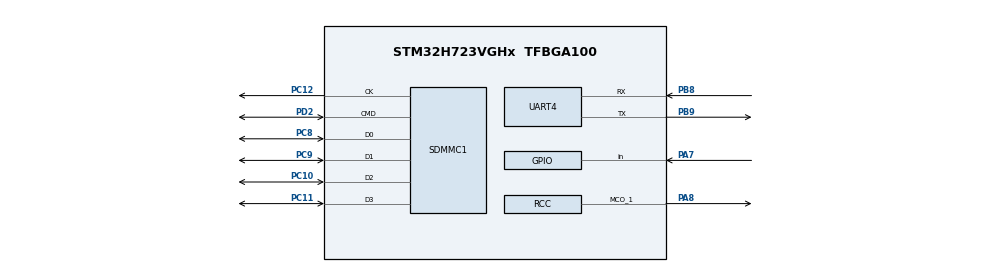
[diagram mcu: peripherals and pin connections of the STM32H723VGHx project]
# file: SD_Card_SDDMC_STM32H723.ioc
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Dma.DMA_GENERATOR0.0.Direction=DMA_PERIPH_TO_MEMORY
Dma.DMA_GENERATOR0.0.EventEnable=DISABLE
Dma.DMA_GENERATOR0.0.FIFOMode=DMA_FIFOMODE_ENABLE
Dma.DMA_GENERATOR0.0.FIFOThreshold=DMA_FIFO_THRESHOLD_FULL
Dma.DMA_GENERATOR0.0.Instance=DMA1_Stream1
Dma.DMA_GENERATOR0.0.MemBurst=DMA_MBURST_SINGLE
Dma.DMA_GENERATOR0.0.MemDataAlignment=DMA_MDATAALIGN_WORD
Dma.DMA_GENERATOR0.0.MemInc=DMA_MINC_ENABLE
Dma.DMA_GENERATOR0.0.Mode=DMA_NORMAL
Dma.DMA_GENERATOR0.0.PeriphBurst=DMA_PBURST_SINGLE
Dma.DMA_GENERATOR0.0.PeriphDataAlignment=DMA_PDATAALIGN_WORD
Dma.DMA_GENERATOR0.0.PeriphInc=DMA_PINC_DISABLE
Dma.DMA_GENERATOR0.0.Polarity=HAL_DMAMUX_REQ_GEN_RISING
Dma.DMA_GENERATOR0.0.Priority=DMA_PRIORITY_LOW
Dma.DMA_GENERATOR0.0.RequestNumber=1
Dma.DMA_GENERATOR0.0.SignalID=NONE
Dma.DMA_GENERATOR0.0.SyncEnable=DISABLE
Dma.DMA_GENERATOR0.0.SyncPolarity=HAL_DMAMUX_SYNC_NO_EVENT
Dma.DMA_GENERATOR0.0.SyncRequestNumber=1
Dma.DMA_GENERATOR0.0.SyncSignalID=NONE
Dma.DMA_GENERATOR1.1.Direction=DMA_MEMORY_TO_PERIPH
Dma.DMA_GENERATOR1.1.EventEnable=DISABLE
Dma.DMA_GENERATOR1.1.FIFOMode=DMA_FIFOMODE_ENABLE
Dma.DMA_GENERATOR1.1.FIFOThreshold=DMA_FIFO_THRESHOLD_FULL
Dma.DMA_GENERATOR1.1.Instance=DMA1_Stream0
Dma.DMA_GENERATOR1.1.MemBurst=DMA_MBURST_SINGLE
Dma.DMA_GENERATOR1.1.MemDataAlignment=DMA_MDATAALIGN_WORD
Dma.DMA_GENERATOR1.1.MemInc=DMA_MINC_ENABLE
Dma.DMA_GENERATOR1.1.Mode=DMA_NORMAL
Dma.DMA_GENERATOR1.1.PeriphBurst=DMA_PBURST_SINGLE
Dma.DMA_GENERATOR1.1.PeriphDataAlignment=DMA_PDATAALIGN_WORD
Dma.DMA_GENERATOR1.1.PeriphInc=DMA_PINC_DISABLE
Dma.DMA_GENERATOR1.1.Polarity=HAL_DMAMUX_REQ_GEN_RISING
Dma.DMA_GENERATOR1.1.Priority=DMA_PRIORITY_LOW
Dma.DMA_GENERATOR1.1.RequestNumber=1
Dma.DMA_GENERATOR1.1.SignalID=NONE
Dma.DMA_GENERATOR1.1.SyncEnable=DISABLE
Dma.DMA_GENERATOR1.1.SyncPolarity=HAL_DMAMUX_SYNC_NO_EVENT
Dma.DMA_GENERATOR1.1.SyncRequestNumber=1
Dma.DMA_GENERATOR1.1.SyncSignalID=NONE
Dma.Request0=DMA_GENERATOR0
Dma.Request1=DMA_GENERATOR1
FATFS.BSP.number=1
FATFS.USE_DMA_CODE_SD=1
FATFS._USE_CHMOD=1
FATFS._USE_EXPAND=1
FATFS._USE_FIND=1
FATFS._USE_FORWARD=1
FATFS._USE_LABEL=1
FATFS._USE_LFN=3
FATFS0.BSP.STBoard=false
FATFS0.BSP.api=Unknown
FATFS0.BSP.instance=PA7
FATFS0.BSP.ip=GPIO
FATFS0.BSP.mode=Input
FATFS0.BSP.name=Detect_SDIO
FATFS0.BSP.solution=PA7
Mcu.Family=STM32H7
Mcu.Name=STM32H723VGHx
Mcu.Package=TFBGA100
NVIC.PriorityGroup=NVIC_PRIORITYGROUP_4
NVIC.SDMMC1_IRQn=true\:0\:0\:false\:false\:true\:true\:true\:true
PA7.Signal=GPIO_Input
PA8.Mode=Clock-out-1
PA8.Signal=RCC_MCO_1
PB8.Mode=Asynchronous
PB8.Signal=UART4_RX
PB9.Mode=Asynchronous
PB9.Signal=UART4_TX
PC10.Mode=SD_4_bits_Wide_bus
PC10.Signal=SDMMC1_D2
PC11.Mode=SD_4_bits_Wide_bus
PC11.Signal=SDMMC1_D3
PC12.Mode=SD_4_bits_Wide_bus
PC12.Signal=SDMMC1_CK
PC8.Mode=SD_4_bits_Wide_bus
PC8.Signal=SDMMC1_D0
PC9.Mode=SD_4_bits_Wide_bus
PC9.Signal=SDMMC1_D1
PD2.Mode=SD_4_bits_Wide_bus
PD2.Signal=SDMMC1_CMD
PH0-OSC_IN.Mode=HSE-External-Oscillator
PH0-OSC_IN.Signal=RCC_OSC_IN
PH1-OSC_OUT.Mode=HSE-External-Oscillator
PH1-OSC_OUT.Signal=RCC_OSC_OUT
ProjectManager.HeapSize=0x200
ProjectManager.StackSize=0x400
ProjectManager.TargetToolchain=STM32CubeIDE
RCC.ADCFreq_Value=50390625
RCC.APB1Freq_Value=137500000
RCC.APB2Freq_Value=137500000
RCC.APB3Freq_Value=137500000
RCC.APB4Freq_Value=137500000
RCC.CortexFreq_Value=550000000
RCC.D1PPRE=RCC_APB3_DIV2
RCC.D2PPRE1=RCC_APB1_DIV2
RCC.D2PPRE2=RCC_APB2_DIV2
RCC.D3PPRE=RCC_APB4_DIV2
RCC.DIVM1=2
RCC.DIVN1=44
RCC.DIVP1=1
RCC.DIVQ1=3
RCC.HCLKFreq_Value=275000000
RCC.HPRE=RCC_HCLK_DIV2
RCC.PLL2FRACN=0
RCC.PLL3FRACN=0
RCC.PLLFRACN=0
RCC.PLLSourceVirtual=RCC_PLLSOURCE_HSE
RCC.SYSCLKFreq_VALUE=550000000
RCC.SYSCLKSource=RCC_SYSCLKSOURCE_PLLCLK
RCC.USART234578CLockSelection=RCC_USART234578CLKSOURCE_HSI
RCC.USBFreq_Value=183333333.33333334
SDMMC1.HardwareFlowControl=SDMMC_HARDWARE_FLOW_CONTROL_ENABLE
VP_FATFS_VS_SDIO.Mode=SDIO
board=custom

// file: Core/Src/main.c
/* USER CODE BEGIN Header */
/**
  ******************************************************************************
  * @file           : main.c
  * @brief          : Main program body
  ******************************************************************************
  * @attention
  *
  * Copyright (c) 2025 STMicroelectronics.
  * All rights reserved.
  *
  * This software is licensed under terms that can be found in the LICENSE file
  * in the root directory of this software component.
  * If no LICENSE file comes with this software, it is provided AS-IS.
  *
  ******************************************************************************
  */
/* USER CODE END Header */
#include "main.h"
#include "fatfs.h"

/* USER CODE BEGIN Includes */

#include <stdio.h>
#include "sd_functions.h"
#include "sd_benchmark.h"

/* USER CODE END Includes */

SD_HandleTypeDef hsd1;

UART_HandleTypeDef huart4;

DMA_HandleTypeDef hdma_dma_generator0;
DMA_HandleTypeDef hdma_dma_generator1;

void SystemClock_Config(void);
static void MX_GPIO_Init(void);
static void MX_DMA_Init(void);
static void MX_SDMMC1_SD_Init(void);
static void MX_UART4_Init(void);
/* USER CODE BEGIN PFP */

/*
 *	Function that print data via UART
 */
int _write(int fd, unsigned char *buf, int len) {
  if (fd == 1 || fd == 2) {
    HAL_UART_Transmit(&huart4, buf, len, 999);  // Print to the UART
  }
  return len;
}

/* USER CODE END PFP */

int main(void)
{

  /* MCU Configuration--------------------------------------------------------*/

  /* Reset of all peripherals, Initializes the Flash interface and the Systick. */
  HAL_Init();

  /* Configure the system clock */
  SystemClock_Config();

  /* Initialize all configured peripherals */
  MX_GPIO_Init();
  MX_DMA_Init();
  MX_SDMMC1_SD_Init();
  MX_FATFS_Init();
  MX_UART4_Init();
  /* USER CODE BEGIN 2 */

  /* !ONLY test speed for read / write. for some project use sd_function */
  sd_benchmark();

  /* USER CODE END 2 */

  /* Infinite loop */
  while (1)
  {

  }
}

void SystemClock_Config(void)
{
  RCC_OscInitTypeDef RCC_OscInitStruct = {0};
  RCC_ClkInitTypeDef RCC_ClkInitStruct = {0};

  /** Supply configuration update enable
  */
  HAL_PWREx_ConfigSupply(PWR_LDO_SUPPLY);

  /** Configure the main internal regulator output voltage
  */
  __HAL_PWR_VOLTAGESCALING_CONFIG(PWR_REGULATOR_VOLTAGE_SCALE0);

  while(!__HAL_PWR_GET_FLAG(PWR_FLAG_VOSRDY)) {}

  /** Initializes the RCC Oscillators according to the specified parameters
  * in the RCC_OscInitTypeDef structure.
  */
  RCC_OscInitStruct.OscillatorType = RCC_OSCILLATORTYPE_HSI|RCC_OSCILLATORTYPE_HSE;
  RCC_OscInitStruct.HSEState = RCC_HSE_ON;
  RCC_OscInitStruct.HSIState = RCC_HSI_DIV1;
  RCC_OscInitStruct.HSICalibrationValue = 64;
  RCC_OscInitStruct.PLL.PLLState = RCC_PLL_ON;
  RCC_OscInitStruct.PLL.PLLSource = RCC_PLLSOURCE_HSE;
  RCC_OscInitStruct.PLL.PLLM = 2;
  RCC_OscInitStruct.PLL.PLLN = 44;
  RCC_OscInitStruct.PLL.PLLP = 1;
  RCC_OscInitStruct.PLL.PLLQ = 3;
  RCC_OscInitStruct.PLL.PLLR = 2;
  RCC_OscInitStruct.PLL.PLLRGE = RCC_PLL1VCIRANGE_3;
  RCC_OscInitStruct.PLL.PLLVCOSEL = RCC_PLL1VCOWIDE;
  RCC_OscInitStruct.PLL.PLLFRACN = 0;
  if (HAL_RCC_OscConfig(&RCC_OscInitStruct) != HAL_OK)
  {
    Error_Handler();
  }

  /** Initializes the CPU, AHB and APB buses clocks
  */
  RCC_ClkInitStruct.ClockType = RCC_CLOCKTYPE_HCLK|RCC_CLOCKTYPE_SYSCLK
                              |RCC_CLOCKTYPE_PCLK1|RCC_CLOCKTYPE_PCLK2
                              |RCC_CLOCKTYPE_D3PCLK1|RCC_CLOCKTYPE_D1PCLK1;
  RCC_ClkInitStruct.SYSCLKSource = RCC_SYSCLKSOURCE_PLLCLK;
  RCC_ClkInitStruct.SYSCLKDivider = RCC_SYSCLK_DIV1;
  RCC_ClkInitStruct.AHBCLKDivider = RCC_HCLK_DIV2;
  RCC_ClkInitStruct.APB3CLKDivider = RCC_APB3_DIV2;
  RCC_ClkInitStruct.APB1CLKDivider = RCC_APB1_DIV2;
  RCC_ClkInitStruct.APB2CLKDivider = RCC_APB2_DIV2;
  RCC_ClkInitStruct.APB4CLKDivider = RCC_APB4_DIV2;

  if (HAL_RCC_ClockConfig(&RCC_ClkInitStruct, FLASH_LATENCY_3) != HAL_OK)
  {
    Error_Handler();
  }
  HAL_RCC_MCOConfig(RCC_MCO1, RCC_MCO1SOURCE_HSI, RCC_MCODIV_1);
}

static void MX_SDMMC1_SD_Init(void)
{

  hsd1.Instance = SDMMC1;
  hsd1.Init.ClockEdge = SDMMC_CLOCK_EDGE_RISING;
  hsd1.Init.ClockPowerSave = SDMMC_CLOCK_POWER_SAVE_DISABLE;
  hsd1.Init.BusWide = SDMMC_BUS_WIDE_4B;
  hsd1.Init.HardwareFlowControl = SDMMC_HARDWARE_FLOW_CONTROL_ENABLE;
  hsd1.Init.ClockDiv = 0;

}

static void MX_UART4_Init(void)
{

  huart4.Instance = UART4;
  huart4.Init.BaudRate = 115200;
  huart4.Init.WordLength = UART_WORDLENGTH_8B;
  huart4.Init.StopBits = UART_STOPBITS_1;
  huart4.Init.Parity = UART_PARITY_NONE;
  huart4.Init.Mode = UART_MODE_TX_RX;
  huart4.Init.HwFlowCtl = UART_HWCONTROL_NONE;
  huart4.Init.OverSampling = UART_OVERSAMPLING_16;
  huart4.Init.OneBitSampling = UART_ONE_BIT_SAMPLE_DISABLE;
  huart4.Init.ClockPrescaler = UART_PRESCALER_DIV1;
  huart4.AdvancedInit.AdvFeatureInit = UART_ADVFEATURE_NO_INIT;
  if (HAL_UART_Init(&huart4) != HAL_OK)
  {
    Error_Handler();
  }
  if (HAL_UARTEx_SetTxFifoThreshold(&huart4, UART_TXFIFO_THRESHOLD_1_8) != HAL_OK)
  {
    Error_Handler();
  }
  if (HAL_UARTEx_SetRxFifoThreshold(&huart4, UART_RXFIFO_THRESHOLD_1_8) != HAL_OK)
  {
    Error_Handler();
  }
  if (HAL_UARTEx_DisableFifoMode(&huart4) != HAL_OK)
  {
    Error_Handler();
  }

}

static void MX_DMA_Init(void)
{

  /* DMA controller clock enable */
  __HAL_RCC_DMA1_CLK_ENABLE();

  /* Configure DMA request hdma_dma_generator0 on DMA1_Stream1 */
  hdma_dma_generator0.Instance = DMA1_Stream1;
  hdma_dma_generator0.Init.Request = DMA_REQUEST_GENERATOR0;
  hdma_dma_generator0.Init.Direction = DMA_PERIPH_TO_MEMORY;
  hdma_dma_generator0.Init.PeriphInc = DMA_PINC_DISABLE;
  hdma_dma_generator0.Init.MemInc = DMA_MINC_ENABLE;
  hdma_dma_generator0.Init.PeriphDataAlignment = DMA_PDATAALIGN_WORD;
  hdma_dma_generator0.Init.MemDataAlignment = DMA_MDATAALIGN_WORD;
  hdma_dma_generator0.Init.Mode = DMA_NORMAL;
  hdma_dma_generator0.Init.Priority = DMA_PRIORITY_LOW;
  hdma_dma_generator0.Init.FIFOMode = DMA_FIFOMODE_ENABLE;
  hdma_dma_generator0.Init.FIFOThreshold = DMA_FIFO_THRESHOLD_FULL;
  hdma_dma_generator0.Init.MemBurst = DMA_MBURST_SINGLE;
  hdma_dma_generator0.Init.PeriphBurst = DMA_PBURST_SINGLE;
  if (HAL_DMA_Init(&hdma_dma_generator0) != HAL_OK)
  {
    Error_Handler( );
  }

  /* Configure DMA request hdma_dma_generator1 on DMA1_Stream0 */
  hdma_dma_generator1.Instance = DMA1_Stream0;
  hdma_dma_generator1.Init.Request = DMA_REQUEST_GENERATOR1;
  hdma_dma_generator1.Init.Direction = DMA_MEMORY_TO_PERIPH;
  hdma_dma_generator1.Init.PeriphInc = DMA_PINC_DISABLE;
  hdma_dma_generator1.Init.MemInc = DMA_MINC_ENABLE;
  hdma_dma_generator1.Init.PeriphDataAlignment = DMA_PDATAALIGN_WORD;
  hdma_dma_generator1.Init.MemDataAlignment = DMA_MDATAALIGN_WORD;
  hdma_dma_generator1.Init.Mode = DMA_NORMAL;
  hdma_dma_generator1.Init.Priority = DMA_PRIORITY_LOW;
  hdma_dma_generator1.Init.FIFOMode = DMA_FIFOMODE_ENABLE;
  hdma_dma_generator1.Init.FIFOThreshold = DMA_FIFO_THRESHOLD_FULL;
  hdma_dma_generator1.Init.MemBurst = DMA_MBURST_SINGLE;
  hdma_dma_generator1.Init.PeriphBurst = DMA_PBURST_SINGLE;
  if (HAL_DMA_Init(&hdma_dma_generator1) != HAL_OK)
  {
    Error_Handler( );
  }

}

static void MX_GPIO_Init(void)
{
  GPIO_InitTypeDef GPIO_InitStruct = {0};

  /* GPIO Ports Clock Enable */
  __HAL_RCC_GPIOB_CLK_ENABLE();
  __HAL_RCC_GPIOD_CLK_ENABLE();
  __HAL_RCC_GPIOC_CLK_ENABLE();
  __HAL_RCC_GPIOH_CLK_ENABLE();
  __HAL_RCC_GPIOA_CLK_ENABLE();

  /*Configure GPIO pin : PA8 */
  GPIO_InitStruct.Pin = GPIO_PIN_8;
  GPIO_InitStruct.Mode = GPIO_MODE_AF_PP;
  GPIO_InitStruct.Pull = GPIO_NOPULL;
  GPIO_InitStruct.Speed = GPIO_SPEED_FREQ_LOW;
  GPIO_InitStruct.Alternate = GPIO_AF0_MCO;
  HAL_GPIO_Init(GPIOA, &GPIO_InitStruct);

  /*Configure GPIO pin : PA7 */
  GPIO_InitStruct.Pin = GPIO_PIN_7;
  GPIO_InitStruct.Mode = GPIO_MODE_INPUT;
  GPIO_InitStruct.Pull = GPIO_NOPULL;
  HAL_GPIO_Init(GPIOA, &GPIO_InitStruct);

}

void Error_Handler(void)
{
  __disable_irq();
  while (1)
  {
  }
}
